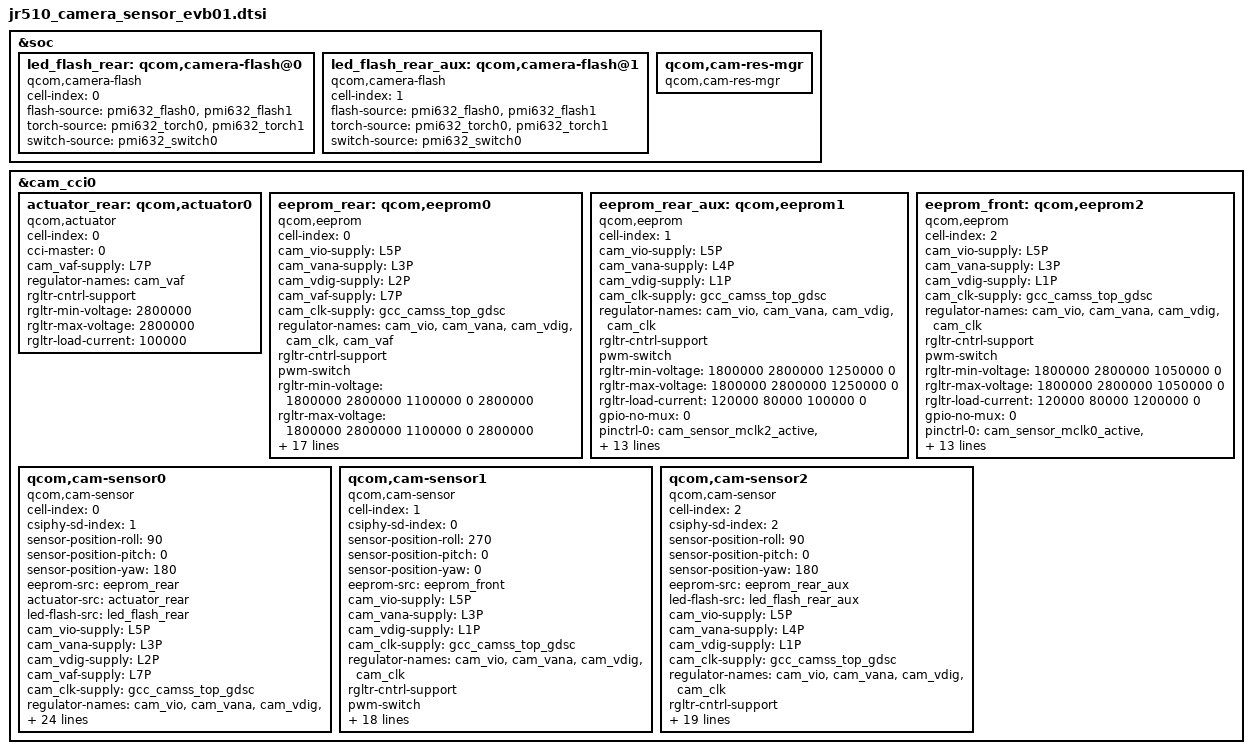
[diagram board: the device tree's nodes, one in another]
#include <dt-bindings/clock/qcom,gcc-bengal.h>
&soc {
	led_flash_rear: qcom,camera-flash@0 {
		cell-index = <0>;
		compatible = "qcom,camera-flash";
		flash-source  = <&pmi632_flash0 &pmi632_flash1>;
		torch-source  = <&pmi632_torch0 &pmi632_torch1>;
		switch-source = <&pmi632_switch0>;
		status = "ok";
	};

	led_flash_rear_aux: qcom,camera-flash@1 {
		cell-index = <1>;
		compatible = "qcom,camera-flash";
		flash-source  = <&pmi632_flash0 &pmi632_flash1>;
		torch-source  = <&pmi632_torch0 &pmi632_torch1>;
		switch-source = <&pmi632_switch0>;
		status = "ok";
	};

	qcom,cam-res-mgr {
		compatible = "qcom,cam-res-mgr";
		status = "ok";
	};
};

&cam_cci0 {

	actuator_rear: qcom,actuator0 {
		cell-index = <0>;
		compatible = "qcom,actuator";
		cci-master = <0>;
		cam_vaf-supply = <&L7P>;
		regulator-names = "cam_vaf";
		rgltr-cntrl-support;
		rgltr-min-voltage = <2800000>;
		rgltr-max-voltage = <2800000>;
		rgltr-load-current = <100000>;
		status = "ok";
	};

	eeprom_rear: qcom,eeprom0 {
		cell-index = <0>;
		compatible = "qcom,eeprom";
		cam_vio-supply = <&L5P>;
		cam_vana-supply = <&L3P>;
		cam_vdig-supply = <&L2P>;
		cam_vaf-supply = <&L7P>;
		cam_clk-supply = <&gcc_camss_top_gdsc>;
		regulator-names = "cam_vio", "cam_vana", "cam_vdig", "cam_clk", "cam_vaf";
		rgltr-cntrl-support;
		pwm-switch;
		rgltr-min-voltage = <1800000 2800000 1100000 0 2800000>;
		rgltr-max-voltage = <1800000 2800000 1100000 0 2800000>;
		rgltr-load-current = <120000 80000 1200000 0 100000>;
		gpio-no-mux = <0>;
		pinctrl-names = "cam_default", "cam_suspend";
		pinctrl-0 = <&cam_sensor_mclk1_active
			&cam_sensor_reset1_active>;
		pinctrl-1 = <&cam_sensor_mclk1_suspend
			&cam_sensor_reset1_suspend>;
		gpios = <&qtang_gpio 7 0>,
			<&qtang_gpio 5 0>;
		gpio-reset = <1>;
		gpio-req-tbl-num = <0 1>;
		gpio-req-tbl-flags = <1 0>;
		gpio-req-tbl-label = "CAMIF_MCLK1",
				"CAM_RESET1";
		sensor-mode = <0>;
		cci-master = <0>;
		status = "ok";
		clocks = <&gcc GCC_CAMSS_MCLK1_CLK>;
		clock-names = "cam_clk";
		clock-cntl-level = "turbo";
		clock-rates = <24000000>;
};

	eeprom_rear_aux: qcom,eeprom1 {
		cell-index = <1>;
		compatible = "qcom,eeprom";
		cam_vio-supply = <&L5P>;
		cam_vana-supply = <&L4P>;
		cam_vdig-supply = <&L1P>;
		cam_clk-supply = <&gcc_camss_top_gdsc>;
		regulator-names = "cam_vio", "cam_vana", "cam_vdig",
				"cam_clk";
		rgltr-cntrl-support;
		pwm-switch;
		rgltr-min-voltage = <1800000 2800000 1250000 0>;
		rgltr-max-voltage = <1800000 2800000 1250000 0>;
		rgltr-load-current = <120000 80000 100000 0>;
		gpio-no-mux = <0>;
		pinctrl-names = "cam_default", "cam_suspend";
		pinctrl-0 = <&cam_sensor_mclk2_active
			&cam_sensor_reset2_active>;
		pinctrl-1 = <&cam_sensor_mclk2_suspend
			&cam_sensor_reset2_suspend>;
		gpios = <&qtang_gpio 13 0>,
			<&qtang_gpio 19 0>;
		gpio-reset = <1>;
		gpio-req-tbl-num = <0 1>;
		gpio-req-tbl-flags = <1 0>;
		gpio-req-tbl-label = "CAMIF_MCLK2",
				"CAM_RESET2";
		sensor-mode = <0>;
		cci-master = <1>;
		status = "ok";
		clocks = <&gcc GCC_CAMSS_MCLK2_CLK>;
		clock-names = "cam_clk";
		clock-cntl-level = "turbo";
		clock-rates = <24000000>;
	};

	eeprom_front: qcom,eeprom2 {
		cell-index = <2>;
		compatible = "qcom,eeprom";
		cam_vio-supply = <&L5P>;
		cam_vana-supply = <&L3P>;
		cam_vdig-supply = <&L1P>;
		cam_clk-supply = <&gcc_camss_top_gdsc>;
		regulator-names = "cam_vio", "cam_vana", "cam_vdig",
				"cam_clk";
		rgltr-cntrl-support;
		pwm-switch;
		rgltr-min-voltage = <1800000 2800000 1050000 0>;
		rgltr-max-voltage = <1800000 2800000 1050000 0>;
		rgltr-load-current = <120000 80000 1200000 0>;
		gpio-no-mux = <0>;
		pinctrl-names = "cam_default", "cam_suspend";
		pinctrl-0 = <&cam_sensor_mclk0_active
			&cam_sensor_reset0_active>;
		pinctrl-1 = <&cam_sensor_mclk0_suspend
			&cam_sensor_reset0_suspend>;
		gpios = <&qtang_gpio 6 0>,
			<&qtang_gpio 4 0>;
		gpio-reset = <1>;
		gpio-req-tbl-num = <0 1>;
		gpio-req-tbl-flags = <1 0>;
		gpio-req-tbl-label = "CAMIF_MCLK0",
				"CAM_RESET0";
		sensor-mode = <0>;
		cci-master = <1>;
		status = "ok";
		clocks = <&gcc GCC_CAMSS_MCLK0_CLK>;
		clock-names = "cam_clk";
		clock-cntl-level = "turbo";
		clock-rates = <24000000>;
  };

//64M
	qcom,cam-sensor0 {
		cell-index = <0>;
		compatible = "qcom,cam-sensor";
		csiphy-sd-index = <1>;
		sensor-position-roll = <90>;
		sensor-position-pitch = <0>;
		sensor-position-yaw = <180>;
		eeprom-src = <&eeprom_rear>;
		actuator-src = <&actuator_rear>;
		led-flash-src = <&led_flash_rear>;
		cam_vio-supply = <&L5P>;
		cam_vana-supply = <&L3P>;
		cam_vdig-supply = <&L2P>;
		cam_vaf-supply = <&L7P>;
		cam_clk-supply = <&gcc_camss_top_gdsc>;
		regulator-names = "cam_vio", "cam_vana", "cam_vdig", "cam_clk", "cam_vaf";
		rgltr-cntrl-support;
		pwm-switch;
		rgltr-min-voltage = <1800000 2800000 1100000 0 2800000>;
		rgltr-max-voltage = <1800000 2800000 1100000 0 2800000>;
		rgltr-load-current = <120000 80000 1200000 0 100000>;
		gpio-no-mux = <0>;
		pinctrl-names = "cam_default", "cam_suspend";
		pinctrl-0 = <&cam_sensor_mclk1_active
			&cam_sensor_reset1_active>;
		pinctrl-1 = <&cam_sensor_mclk1_suspend
			&cam_sensor_reset1_suspend>;
		gpios = <&qtang_gpio 7 0>,
			<&qtang_gpio 5 0>;
		gpio-reset = <1>;
		gpio-req-tbl-num = <0 1>;
		gpio-req-tbl-flags = <1 0>;
		gpio-req-tbl-label = "CAMIF_MCLK1",
				"CAM_RESET1";
		sensor-mode = <0>;
		cci-master = <0>;
		status = "ok";
		clocks = <&gcc GCC_CAMSS_MCLK1_CLK>;
		clock-names = "cam_clk";
		clock-cntl-level = "turbo";
		clock-rates = <24000000>;
	};

//16M
	qcom,cam-sensor1 {
		cell-index = <1>;
		compatible = "qcom,cam-sensor";
		csiphy-sd-index = <0>;
		sensor-position-roll = <270>;
		sensor-position-pitch = <0>;
		sensor-position-yaw = <0>;
		eeprom-src = <&eeprom_front>;
		cam_vio-supply = <&L5P>;
		cam_vana-supply = <&L3P>;
		cam_vdig-supply = <&L1P>;
		cam_clk-supply = <&gcc_camss_top_gdsc>;
		regulator-names = "cam_vio", "cam_vana", "cam_vdig",
				"cam_clk";
		rgltr-cntrl-support;
		pwm-switch;
		rgltr-min-voltage = <1800000 2800000 1200000 0>;
		rgltr-max-voltage = <1800000 2800000 1200000 0>;
		rgltr-load-current = <120000 80000 1200000 0>;
		gpio-no-mux = <0>;
		pinctrl-names = "cam_default", "cam_suspend";
		pinctrl-0 = <&cam_sensor_mclk0_active
			&cam_sensor_reset0_active>;
		pinctrl-1 = <&cam_sensor_mclk0_suspend
			&cam_sensor_reset0_suspend>;
		gpios = <&qtang_gpio 6 0>,
			<&qtang_gpio 4 0>;
		gpio-reset = <1>;
		gpio-req-tbl-num = <0 1>;
		gpio-req-tbl-flags = <1 0>;
		gpio-req-tbl-label = "CAMIF_MCLK0",
				"CAM_RESET0";
		sensor-mode = <0>;
		cci-master = <1>;
		status = "ok";
		clocks = <&gcc GCC_CAMSS_MCLK0_CLK>;
		clock-names = "cam_clk";
		clock-cntl-level = "turbo";
		clock-rates = <24000000>;
	};

//2M
	qcom,cam-sensor2 {
		cell-index = <2>;
		compatible = "qcom,cam-sensor";
		csiphy-sd-index = <2>;
		sensor-position-roll = <90>;
		sensor-position-pitch = <0>;
		sensor-position-yaw = <180>;
		eeprom-src = <&eeprom_rear_aux>;
		led-flash-src = <&led_flash_rear_aux>;
		cam_vio-supply = <&L5P>;
		cam_vana-supply = <&L4P>;
		cam_vdig-supply = <&L1P>;
		cam_clk-supply = <&gcc_camss_top_gdsc>;
		regulator-names = "cam_vio", "cam_vana", "cam_vdig",
				"cam_clk";
		rgltr-cntrl-support;
		pwm-switch;
		rgltr-min-voltage = <1800000 2800000 1250000 0>;
		rgltr-max-voltage = <1800000 2800000 1250000 0>;
		rgltr-load-current = <120000 80000 100000 0>;
		gpio-no-mux = <0>;
		pinctrl-names = "cam_default", "cam_suspend";
		pinctrl-0 = <&cam_sensor_mclk2_active
			&cam_sensor_reset2_active>;
		pinctrl-1 = <&cam_sensor_mclk2_suspend
			&cam_sensor_reset2_suspend>;
		gpios = <&qtang_gpio 13 0>,
			<&qtang_gpio 19 0>;
		gpio-reset = <1>;
		gpio-req-tbl-num = <0 1>;
		gpio-req-tbl-flags = <1 0>;
		gpio-req-tbl-label = "CAMIF_MCLK2",
				"CAM_RESET2";
		sensor-mode = <0>;
		cci-master = <1>;
		status = "ok";
		clocks = <&gcc GCC_CAMSS_MCLK2_CLK>;
		clock-names = "cam_clk";
		clock-cntl-level = "turbo";
		clock-rates = <24000000>;
	};
};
